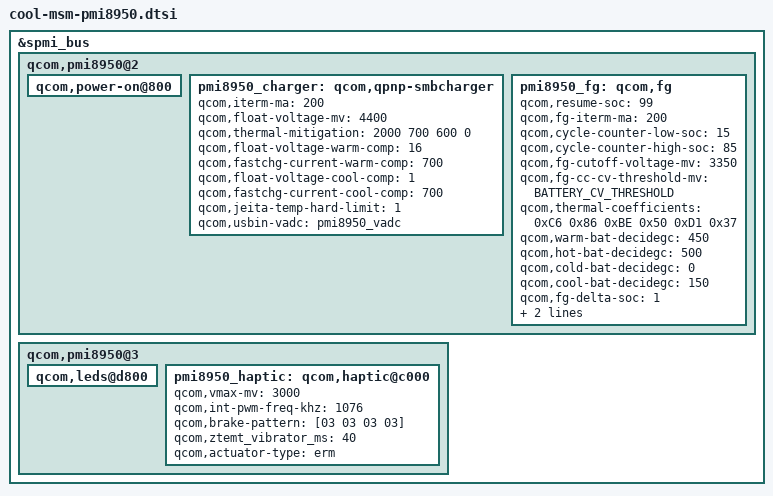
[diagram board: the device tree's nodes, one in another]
/* Copyright (c) 2015, The Linux Foundation. All rights reserved.
 *
 * This program is free software; you can redistribute it and/or modify
 * it under the terms of the GNU General Public License version 2 and
 * only version 2 as published by the Free Software Foundation.
 *
 * This program is distributed in the hope that it will be useful,
 * but WITHOUT ANY WARRANTY; without even the implied warranty of
 * MERCHANTABILITY or FITNESS FOR A PARTICULAR PURPOSE.  See the
 * GNU General Public License for more details.
 */


#define BATTERY_LIMIT_VOLTAGE	(4400)
#define BATTERY_CV_THRESHOLD (BATTERY_LIMIT_VOLTAGE-20)

&spmi_bus {

	qcom,pmi8950@2 {

		qcom,power-on@800 {
			/delete-property/ pon_perph_reg;
		};

		pmi8950_charger: qcom,qpnp-smbcharger {
			qcom,iterm-ma = <200>;
			qcom,float-voltage-mv = <4400>;
			qcom,thermal-mitigation = <2000 700 600 0>;
			/delete-property/ qcom,parallel-usb-min-current-ma;
			/delete-property/ qcom,parallel-usb-9v-min-current-ma;
			/delete-property/ qcom,parallel-allowed-lowering-ma;
			/delete-property/ qcom,charge-unknown-battery;
			qcom,float-voltage-warm-comp = <16>;
			qcom,fastchg-current-warm-comp = <700>;
			qcom,float-voltage-cool-comp = <1>;
			qcom,fastchg-current-cool-comp = <700>;
			qcom,jeita-temp-hard-limit = <1>;
			qcom,usbin-vadc = <&pmi8950_vadc>;

		};

		pmi8950_fg: qcom,fg {
			qcom,resume-soc = <99>;
			qcom,fg-iterm-ma = <200>;
			qcom,cycle-counter-low-soc = <15>;
			qcom,cycle-counter-high-soc = <85>;
			qcom,fg-cutoff-voltage-mv = <3350>;
			qcom,fg-cc-cv-threshold-mv = <BATTERY_CV_THRESHOLD>;
			qcom,thermal-coefficients = <0xC6 0x86 0xBE 0x50 0xD1 0x37>;
			qcom,warm-bat-decidegc = <450>;
			qcom,hot-bat-decidegc = <500>;
			qcom,cold-bat-decidegc = <0>;
			qcom,cool-bat-decidegc = <150>;
			qcom,fg-delta-soc = <1>;
			qcom,ext-sense-type;
			qcom,hold-soc-while-full;
		};
	};

	qcom,pmi8950@3 {

		qcom,leds@d800 {
			/delete-property/ qcom,en-phase-stag;
		};
		pmi8950_haptic: qcom,haptic@c000 {
			qcom,vmax-mv = <3000>;
			qcom,int-pwm-freq-khz = <1076>;
			qcom,brake-pattern = [03 03 03 03];
			qcom,ztemt_vibrator_ms = <40>;
			qcom,actuator-type = "erm";
		};
	};
};
